# SPC1068 register map
File version: 20180100_70611510
CPU: CM3 r2p1, little endian, MPU, no FPU, 4 interrupt priority bits
Registers are 32-bit, read-write, reset 0x0 unless marked. A register's access mark holds for its fields unless they carry their own. Offsets are from the block's base; [hi:lo] are bit positions; {n}, {i} and the like mark numbered series; 'fields as' and 'values as' point back to an identical list.

## AES
Base 0x41000400
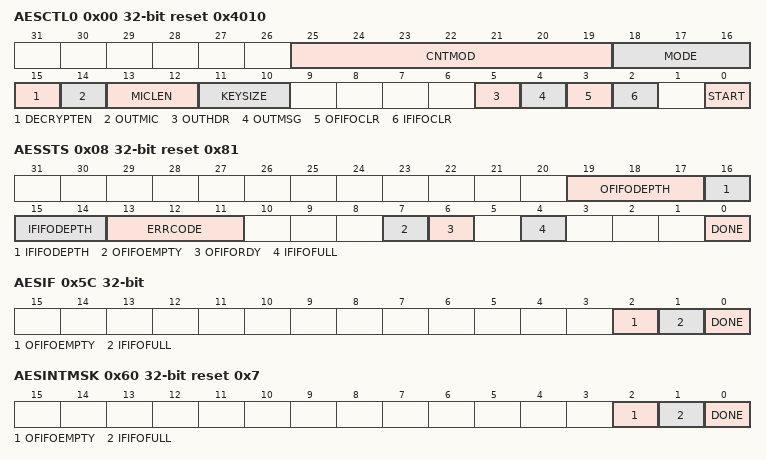
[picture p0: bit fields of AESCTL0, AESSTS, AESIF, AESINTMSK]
0x00 AESCTL0 reset 0x4010 — AES Control Register 0
  [25:19] CNTMOD — CTR mode's counter modular modular=2^128:[7'h0-7'hF] modular=2^ctr_mod: others
  [18:16] MODE — AES running mode
    0=ECB; 1=CBC; 2=CTR; 5=CCM; 6=MMO; 7=BYPASS
  [15] DECRYPTEN — Decrypt operation. Ignored in MMO and BYPASS Mode.
    0=ENCRYPT (Encryption); 1=DECRYPT (Decryption)
  [14] OUTMIC — Append MIC/HASH at the end of output stream in CCM* mode encryption/MMO mode.
    0=DISABLE (Not append MIC/HASH at the end of output stream in CCM* mode encryption or MMO mode); 1=ENABLE (Append MIC/HASH at the end of output stream in CCM* mode encryption or MMO mode)
  [13:12] MICLEN — Length of MIC field
    0=0BYTE (0 bytes); 1=4BYTE (4 bytes); 2=8BYTE (8 bytes); 3=16BYTE (16 bytes)
  [11:10] KEYSIZE — Key size parameter
    0=16BYTE (16 bytes); 1=32BYTE (32 bytes); 2=24BYTE (24 bytes)
  [5] OUTHDR — Output B0 and l(a) in CCM* mode
    0=DISABLE (Don't output B0 and l(a) at the beginning of output stream); 1=ENABLE (Output B0 and l(a) at the beginning of output stream)
  [4] OUTMSG — Output stream to output FIFO
    0=DISABLE (Block output stream from output FIFO); 1=ENABLE (Forward output stream to output FIFO)
  [3] OFIFOCLR wo — Clear output FIFO
    0=NO_EFFECT (None); 1=CLEAR_OUTPUT_FIFO (Write '1' will generate one-cycle pulse to clear output FIFO)
  [2] IFIFOCLR wo — Clear input FIFO
    0=NO_EFFECT (None); 1=CLEAR_INPUT_FIFO (Write '1' will generate one-cycle pulse to clear input FIFO)
  [0] START wo — Start AES
    0=NO_EFFECT (None); 1=AES_START (Write '1' will generate one-cycle pulse to start AES operation)
0x04 AESCTL1 — AES Control Register 1
  [0] RST — Reset AES
    0=AES_NOT_RESET (Un-reset AES); 1=AES_RESET (Reset AES, please set to 0 manually)
0x08 AESSTS ro reset 0x81 — AES Status Register
  [19:17] OFIFODEPTH — The output FIFO depth
  [16:14] IFIFODEPTH — The input FIFO depth
  [13:11] ERRCODE — AES operation error status
    0=NO_ERROR (No operation error); 1=Input stream size less than 16 byte in ECB, CBC and CTR mode; 2=Data is not multiple of 16 bytes in ECB mode or Data is more than 2^13-1 bytes in MMO mode; 3=Data is not multiple of 16 bytes and less than 16 bytes in ECB mode; 4=MIC Mismatch during CCM* Decryption
  [7] OFIFOEMPTY — Output FIFO empty
    0=NOT_EMPTY (Output FIFO is not empty); 1=EMPTY (Output FIFO is empty)
  [6] OFIFORDY — Output FIFO is ready to read
    0=NOT_READY (Output FIFO is not ready to read); 1=READY (Output FIFO is ready to read)
  [4] IFIFOFULL — Input FIFO full
    0=NOT_FULL (Input FIFO is not full); 1=FULL (Input FIFO is full)
  [0] DONE — AES operation done
    0=OPERATION_NOT_DONE (AES operation has not done yet); 1=OPERATION_DONE (AES operation done)
0x0C AESASTRLEN — AES Associate String Length Register
  [31:0] VAL — Size of associate string
0x10 AESMSTRLEN — AES Message String Length Register
  [31:0] VAL — Size of message string
0x14 AESSTRIN wo — AES Input Message Word Register
  [31:0] VAL — Input message word
{0x18+4i} AESIV[{i}] (i=0..3) — AES Initial Vector Register 0
  [31:0] VAL — Byte 0-3 of initial vector
{0x28+4i} AESKEY[{i}] (i=0..7) — AES Key Register 0
  [31:0] VAL — Byte 0-3 of key
0x48 AESSTROUT ro — AES Output Message Word Register
  [31:0] VAL — Output message word
{0x4C+4i} AESOV[{i}] (i=0..3) ro — AES Output Vector Register 0
  [31:0] VAL — Byte 0-3 of output vector
0x5C AESIF ro — AES Interrupt Status Register
  [2] OFIFOEMPTY — Status of AES output FIFO empty interrupt
    0=NOT_OCCUR (AES output FIFO empty interrupt not occurred); 1=OCCUR (AES output FIFO empty interrupt occurred)
  [1] IFIFOFULL — Status of AES input FIFO full interrupt
    0=NOT_OCCUR (AES input FIFO full interrupt not occurred); 1=OCCUR (AES input FIFO full interrupt occurred)
  [0] DONE — Status of AES operation done interrupt
    0=NOT_OCCUR (AES operation done interrupt not occurred); 1=OCCUR (AES operation done interrupt occurred)
0x60 AESINTMSK reset 0x7 — AES Interrupt Mask Register
  [2] OFIFOEMPTY — Mask of AES output FIFO empty interrupt
    0=UNMASK (Enable AES output FIFO empty interrupt); 1=MASK (Disable AES output FIFO empty interrupt)
  [1] IFIFOFULL — Mask of AES input FIFO full interrupt
    0=UNMASK (Enable AES input FIFO full interrupt); 1=MASK (Disable AES input FIFO full interrupt)
  [0] DONE — Mask of AES operation done interrupt
    0=UNMASK (Enable AES operation done interrupt); 1=MASK (Disable AES operation done interrupt)
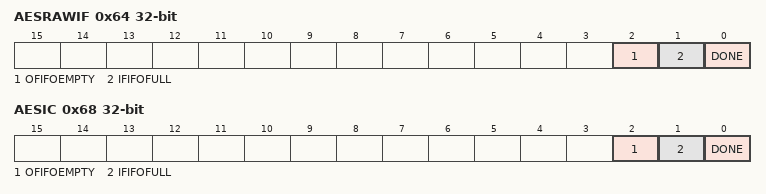
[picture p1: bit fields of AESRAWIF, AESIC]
0x64 AESRAWIF ro — AES Interrupt RAW status Register
  [2] OFIFOEMPTY — AES output FIFO empty interrupt raw status regardless of mask
    0=NOT_OCCUR (AES output FIFO empty interrupt not occurred); 1=OCCUR (AES output FIFO empty interrupt)
  [1] IFIFOFULL — AES input FIFO full interrupt raw status regardless of mask
    0=NOT_OCCUR (AES no input FIFO full interrupt not occurred); 1=OCCUR (AES no input FIFO full interrupt occurred)
  [0] DONE — AES operation done interrupt raw status regardless of mask
    values as AESIF.DONE
0x68 AESIC — AES Interrupt Clear Register
  [2] OFIFOEMPTY — Clearance of AES output FIFO empty interrupt status and raw status
    0=NO_EFFECT (None); 1=CLEAR_FLAG (Write '1' will generate a single-cycle pulse that clears both AES output FIFO empty interrupt status and raw status)
  [1] IFIFOFULL — Clearance of AES input FIFO full interrupt status and raw status
    0=NO_EFFECT (None); 1=CLEAR_FLAG (Write '1' will generate a single-cycle pulse that clears both AES input FIFO full interrupt status and raw status)
  [0] DONE — Clearance of AES operation done interrupt status and raw status
    0=NO_EFFECT (None); 1=CLEAR_FLAG (Write '1' will generate a single-cycle pulse that clears both AES operation done interrupt status and raw status)
